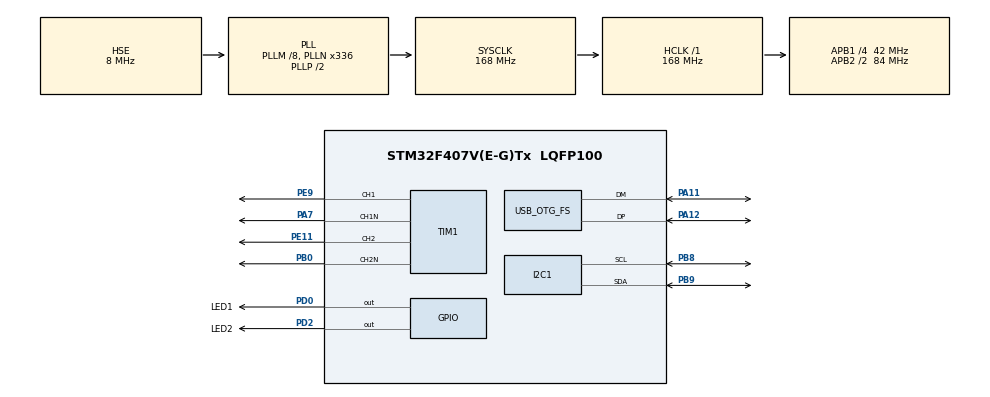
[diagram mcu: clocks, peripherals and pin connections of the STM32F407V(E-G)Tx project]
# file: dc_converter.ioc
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FREERTOS.Tasks01=defaultTask,24,128,StartDefaultTask,Default,NULL,Dynamic,NULL,NULL;LED1,8,128,LED1_Task,Default,NULL,Dynamic,NULL,NULL
Mcu.Family=STM32F4
Mcu.Name=STM32F407V(E-G)Tx
Mcu.Package=LQFP100
NVIC.OTG_FS_IRQn=true\:5\:0\:false\:false\:true\:true\:false\:true\:true
NVIC.PriorityGroup=NVIC_PRIORITYGROUP_4
NVIC.TIM2_IRQn=true\:15\:0\:false\:false\:true\:false\:false\:true\:true
NVIC.TimeBase=TIM2_IRQn
NVIC.TimeBaseIP=TIM2
PA11.Mode=Device_Only
PA11.Signal=USB_OTG_FS_DM
PA12.Mode=Device_Only
PA12.Signal=USB_OTG_FS_DP
PA13.Mode=Serial_Wire
PA13.Signal=SYS_JTMS-SWDIO
PA14.Mode=Serial_Wire
PA14.Signal=SYS_JTCK-SWCLK
PA7.Mode=Output Compare1 CH1 CH1N
PA7.Signal=TIM1_CH1N
PB0.Mode=Output Compare2 CH2 CH2N
PB0.Signal=TIM1_CH2N
PB8.Mode=I2C
PB8.Signal=I2C1_SCL
PB9.Mode=I2C
PB9.Signal=I2C1_SDA
PD0.GPIO_Label=LED1
PD0.Signal=GPIO_Output
PD2.GPIO_Label=LED2
PD2.Signal=GPIO_Output
PE11.Signal=S_TIM1_CH2
PE9.Signal=S_TIM1_CH1
PH0-OSC_IN.Mode=HSE-External-Oscillator
PH0-OSC_IN.Signal=RCC_OSC_IN
PH1-OSC_OUT.Mode=HSE-External-Oscillator
PH1-OSC_OUT.Signal=RCC_OSC_OUT
ProjectManager.HeapSize=0x400
ProjectManager.StackSize=0x400
ProjectManager.TargetToolchain=MDK-ARM V5.32
RCC.48MHZClocksFreq_Value=48000000
RCC.AHBFreq_Value=168000000
RCC.APB1CLKDivider=RCC_HCLK_DIV4
RCC.APB1Freq_Value=42000000
RCC.APB1TimFreq_Value=84000000
RCC.APB2CLKDivider=RCC_HCLK_DIV2
RCC.APB2Freq_Value=84000000
RCC.APB2TimFreq_Value=168000000
RCC.CortexFreq_Value=168000000
RCC.HCLKFreq_Value=168000000
RCC.HSE_VALUE=8000000
RCC.HSI_VALUE=16000000
RCC.LSE_VALUE=32768
RCC.PLLM=8
RCC.PLLN=336
RCC.PLLQ=7
RCC.SYSCLKFreq_VALUE=168000000
RCC.SYSCLKSource=RCC_SYSCLKSOURCE_PLLCLK
RCC.VCOOutputFreq_Value=336000000
SH.S_TIM1_CH1.0=TIM1_CH1,Output Compare1 CH1 CH1N
SH.S_TIM1_CH2.0=TIM1_CH2,Output Compare2 CH2 CH2N
TIM1.Channel-Output\ Compare1\ CH1\ CH1N=TIM_CHANNEL_1
TIM1.Channel-Output\ Compare2\ CH2\ CH2N=TIM_CHANNEL_2
USB_DEVICE.APP_RX_DATA_SIZE-CDC_FS=2048
USB_DEVICE.CLASS_NAME_FS=CDC
USB_DEVICE.VirtualMode-CDC_FS=Cdc
USB_DEVICE.VirtualModeFS=Cdc_FS
USB_OTG_FS.VirtualMode=Device_Only
VP_FREERTOS_VS_CMSIS_V2.Mode=CMSIS_V2
VP_SYS_VS_tim2.Mode=TIM2
VP_TIM1_VS_ClockSourceINT.Mode=Internal
VP_USB_DEVICE_VS_USB_DEVICE_CDC_FS.Mode=CDC_FS
board=custom

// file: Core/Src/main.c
/* USER CODE BEGIN Header */
/**
  ******************************************************************************
  * @file           : main.c
  * @brief          : Main program body
  ******************************************************************************
  * @attention
  *
  * Copyright (c) 2024 STMicroelectronics.
  * All rights reserved.
  *
  * This software is licensed under terms that can be found in the LICENSE file
  * in the root directory of this software component.
  * If no LICENSE file comes with this software, it is provided AS-IS.
  *
  ******************************************************************************
  */
/* USER CODE END Header */
#include "main.h"
#include "cmsis_os.h"
#include "i2c.h"
#include "tim.h"
#include "usb_device.h"
#include "gpio.h"

/* USER CODE BEGIN Includes */
#include "usbd_cdc_if.h"
/* USER CODE END Includes */

void SystemClock_Config(void);
void MX_FREERTOS_Init(void);

int main(void)
{

  /* MCU Configuration--------------------------------------------------------*/

  /* Reset of all peripherals, Initializes the Flash interface and the Systick. */
  HAL_Init();

  /* Configure the system clock */
  SystemClock_Config();

  /* Initialize all configured peripherals */
  MX_GPIO_Init();
  MX_TIM1_Init();
  MX_I2C1_Init();

  /* Init scheduler */
  osKernelInitialize();  /* Call init function for freertos objects (in freertos.c) */
  MX_FREERTOS_Init();

  /* Start scheduler */
  osKernelStart();

  /* We should never get here as control is now taken by the scheduler */
  /* Infinite loop */
  while (1)
  {

  }
}

void SystemClock_Config(void)
{
  RCC_OscInitTypeDef RCC_OscInitStruct = {0};
  RCC_ClkInitTypeDef RCC_ClkInitStruct = {0};

  /** Configure the main internal regulator output voltage
  */
  __HAL_RCC_PWR_CLK_ENABLE();
  __HAL_PWR_VOLTAGESCALING_CONFIG(PWR_REGULATOR_VOLTAGE_SCALE1);

  /** Initializes the RCC Oscillators according to the specified parameters
  * in the RCC_OscInitTypeDef structure.
  */
  RCC_OscInitStruct.OscillatorType = RCC_OSCILLATORTYPE_HSE;
  RCC_OscInitStruct.HSEState = RCC_HSE_ON;
  RCC_OscInitStruct.PLL.PLLState = RCC_PLL_ON;
  RCC_OscInitStruct.PLL.PLLSource = RCC_PLLSOURCE_HSE;
  RCC_OscInitStruct.PLL.PLLM = 8;
  RCC_OscInitStruct.PLL.PLLN = 336;
  RCC_OscInitStruct.PLL.PLLP = RCC_PLLP_DIV2;
  RCC_OscInitStruct.PLL.PLLQ = 7;
  if (HAL_RCC_OscConfig(&RCC_OscInitStruct) != HAL_OK)
  {
    Error_Handler();
  }

  /** Initializes the CPU, AHB and APB buses clocks
  */
  RCC_ClkInitStruct.ClockType = RCC_CLOCKTYPE_HCLK|RCC_CLOCKTYPE_SYSCLK
                              |RCC_CLOCKTYPE_PCLK1|RCC_CLOCKTYPE_PCLK2;
  RCC_ClkInitStruct.SYSCLKSource = RCC_SYSCLKSOURCE_PLLCLK;
  RCC_ClkInitStruct.AHBCLKDivider = RCC_SYSCLK_DIV1;
  RCC_ClkInitStruct.APB1CLKDivider = RCC_HCLK_DIV4;
  RCC_ClkInitStruct.APB2CLKDivider = RCC_HCLK_DIV2;

  if (HAL_RCC_ClockConfig(&RCC_ClkInitStruct, FLASH_LATENCY_5) != HAL_OK)
  {
    Error_Handler();
  }
}

void HAL_TIM_PeriodElapsedCallback(TIM_HandleTypeDef *htim)
{
  if (htim->Instance == TIM2) {
    HAL_IncTick();
  }
}

void Error_Handler(void)
{
  __disable_irq();
  while (1)
  {
  }
}

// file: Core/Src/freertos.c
/* USER CODE BEGIN Header */
/**
  ******************************************************************************
  * File Name          : freertos.c
  * Description        : Code for freertos applications
  ******************************************************************************
  * @attention
  *
  * Copyright (c) 2024 STMicroelectronics.
  * All rights reserved.
  *
  * This software is licensed under terms that can be found in the LICENSE file
  * in the root directory of this software component.
  * If no LICENSE file comes with this software, it is provided AS-IS.
  *
  ******************************************************************************
  */
/* USER CODE END Header */

#include "FreeRTOS.h"
#include "task.h"
#include "main.h"
#include "cmsis_os.h"

/* Definitions for defaultTask */
osThreadId_t defaultTaskHandle;
const osThreadAttr_t defaultTask_attributes = {
  .name = "defaultTask",
  .stack_size = 128 * 4,
  .priority = (osPriority_t) osPriorityNormal,
};
/* Definitions for LED1 */
osThreadId_t LED1Handle;
const osThreadAttr_t LED1_attributes = {
  .name = "LED1",
  .stack_size = 128 * 4,
  .priority = (osPriority_t) osPriorityLow,
};

void StartDefaultTask(void *argument);
void LED1_Task(void *argument);

extern void MX_USB_DEVICE_Init(void);
void MX_FREERTOS_Init(void); /* (MISRA C 2004 rule 8.1) */

void MX_FREERTOS_Init(void) {

  /* Create the thread(s) */
  /* creation of defaultTask */
  defaultTaskHandle = osThreadNew(StartDefaultTask, NULL, &defaultTask_attributes);

  /* creation of LED1 */
  LED1Handle = osThreadNew(LED1_Task, NULL, &LED1_attributes);

}

void StartDefaultTask(void *argument)
{
  /* init code for USB_DEVICE */
  MX_USB_DEVICE_Init();
  for(;;)
  {
    osDelay(1);
  }
}

void LED1_Task(void *argument)
{
  /* USER CODE BEGIN LED1_Task */
  /* Infinite loop */
  for(;;)
  {
    HAL_GPIO_TogglePin(LED1_GPIO_Port,LED1_Pin);
		usb_printf("program once running!");
		HAL_Delay(100);
    osDelay(1);
  }
  /* USER CODE END LED1_Task */
}
